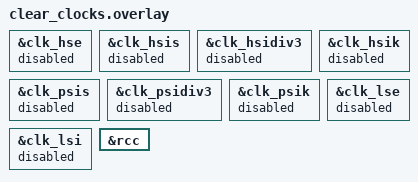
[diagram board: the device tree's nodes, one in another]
/*
 * Copyright (c) 2026 STMicroelectronics
 *
 * SPDX-License-Identifier: Apache-2.0
 */

/*
 * Warning: This overlay clears clocks back to a state equivalent to what could
 * be found in stm32c5.dtsi
 */

&clk_hse {
	status = "disabled";
	/delete-property/ clock-frequency;
	/delete-property/ hse-bypass;
};

&clk_hsis {
	status = "disabled";
};

&clk_hsidiv3 {
	status = "disabled";
};

&clk_hsik {
	status = "disabled";
	/delete-property/ xsik-div;
};

&clk_psis {
	status = "disabled";
	/delete-property/ clock-frequency;
};

&clk_psidiv3 {
	status = "disabled";
	/delete-property/ clock-frequency;
};

&clk_psik {
	status = "disabled";
	/delete-property/ xsik-div;
	/delete-property/ clock-frequency;
};

&clk_lse {
	status = "disabled";
};

&clk_lsi {
	status = "disabled";
};

&rcc {
	/delete-property/ clocks;
	/delete-property/ clock-frequency;
	/delete-property/ ahb-prescaler;
	/delete-property/ apb1-prescaler;
	/delete-property/ apb2-prescaler;
	/delete-property/ apb4-prescaler;
	/delete-property/ st,psi-source;
	/delete-property/ st,psi-frequency;
};
